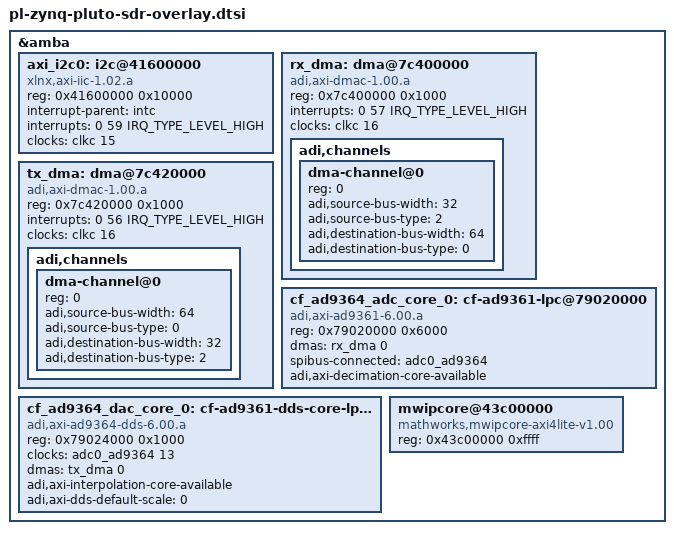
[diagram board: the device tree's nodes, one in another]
#include <dt-bindings/input/input.h>
#include <dt-bindings/gpio/gpio.h>
#include <dt-bindings/interrupt-controller/irq.h>

/ {
	fragment@2 {
		target = <&amba>;
		overlay2: __overlay__ {
			#address-cells = <1>;
			#size-cells = <1>;

			axi_i2c0: i2c@41600000 {
				compatible = "xlnx,axi-iic-1.02.a", "xlnx,xps-iic-2.00.a";
				reg = <0x41600000 0x10000>;
				interrupt-parent = <&intc>;
				interrupts = <0 59 IRQ_TYPE_LEVEL_HIGH>;
				clocks = <&clkc 15>;
				clock-names = "pclk";

				#address-cells = <1>;
				#size-cells = <0>;
			};

			rx_dma: dma@7c400000 {
				compatible = "adi,axi-dmac-1.00.a";
				reg = <0x7c400000 0x1000>;
				#dma-cells = <1>;
				interrupts = <0 57 IRQ_TYPE_LEVEL_HIGH>;
				clocks = <&clkc 16>;

				adi,channels {
					#size-cells = <0>;
					#address-cells = <1>;

					dma-channel@0 {
						reg = <0>;
						adi,source-bus-width = <32>;
						adi,source-bus-type = <2>;
						adi,destination-bus-width = <64>;
						adi,destination-bus-type = <0>;
					};
				};
			};

			tx_dma: dma@7c420000 {
				compatible = "adi,axi-dmac-1.00.a";
				reg = <0x7c420000 0x1000>;
				#dma-cells = <1>;
				interrupts = <0 56 IRQ_TYPE_LEVEL_HIGH>;
				clocks = <&clkc 16>;

				adi,channels {
					#size-cells = <0>;
					#address-cells = <1>;

					dma-channel@0 {
						reg = <0>;
						adi,source-bus-width = <64>;
						adi,source-bus-type = <0>;
						adi,destination-bus-width = <32>;
						adi,destination-bus-type = <2>;
					};
				};
			};

			cf_ad9364_adc_core_0: cf-ad9361-lpc@79020000 {
				compatible = "adi,axi-ad9361-6.00.a";
				reg = <0x79020000 0x6000>;
				dmas = <&rx_dma 0>;
				dma-names = "rx";
				spibus-connected = <&adc0_ad9364>;
				adi,axi-decimation-core-available;
			};

			cf_ad9364_dac_core_0: cf-ad9361-dds-core-lpc@79024000 {
				compatible = "adi,axi-ad9364-dds-6.00.a";
				reg = <0x79024000 0x1000>;
				clocks = <&adc0_ad9364 13>;
				clock-names = "sampl_clk";
				dmas = <&tx_dma 0>;
				dma-names = "tx";
				adi,axi-interpolation-core-available;
				adi,axi-dds-default-scale = <0>;
			};

			mwipcore@43c00000 {
				compatible = "mathworks,mwipcore-axi4lite-v1.00";
				reg = <0x43c00000 0xffff>;
			};
		};
	};
};
